# MMCHS1 register map
Vendor: Texas Instruments
Registers are 32-bit, access per field, reset 0x0 unless marked. A register's access mark holds for its fields unless they carry their own. Offsets are as the file gives them; [hi:lo] are bit positions; {n}, {i} and the like mark numbered series.

## MMCHS1 (part 2 of 2)
0x00 MMCHS_HL_REV ro reset not defined — IP Revision Identifier (X.Y.R) Used by software to track features, bugs, and compatibility
  [31:0] REVISION — IP Revision.
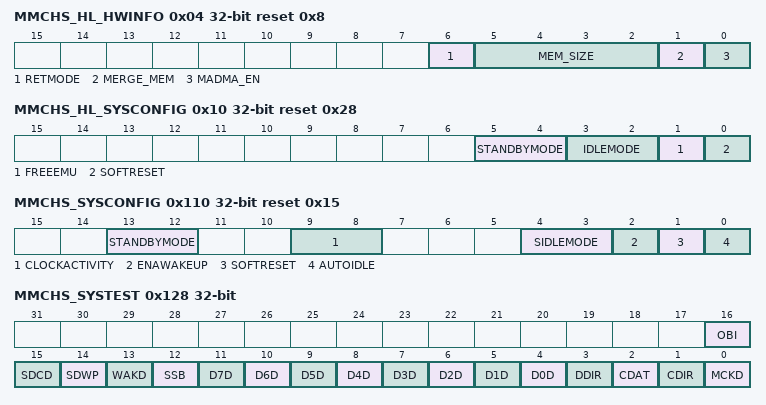
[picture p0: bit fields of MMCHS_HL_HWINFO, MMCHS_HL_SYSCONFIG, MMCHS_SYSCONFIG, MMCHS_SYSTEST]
0x04 MMCHS_HL_HWINFO ro reset 0x8 (reset mask 0xFFFFFFBE) — Information about the IP module's hardware configuration, that is, typically the module's HDL generics (if any). Actual field format and encoding is up to the module's designer to decide.
  [6] RETMODE — Retention mode generic parameter This bit field indicates whether the retention mode is supported using the pin PIRFFRET.
    0=Retention mode disabled; 1=Retention mode enabled
  [5:2] MEM_SIZE — Memory size for FIFO buffer:
    1=MEM_SIZE_1_r (Memory of 512 bytes, max block length is 512 bytes); 2=MEM_SIZE_2_r (Memory of 1024 bytes, max block length is 1024 bytes); 4=MEM_SIZE_4_r (Memory of 2048 bytes, max block length is 2048 bytes); 8=MEM_SIZE_8_r (Memory of 4096 bytes, max block length is 2048 bytes)
  [1] MERGE_MEM — Memory merged for FIFO buffer: This register defines the configuration of FIFO buffer architecture. If the bit is set STA and DFT shall support clock multiplexing and balancing.
    0=MERGE_MEM_0_r (2 memories instantiated, one per data transfer direction.); 1=MERGE_MEM_1_r (A single memory is used with multiplexed addresses, data and clocks.)
  [0] MADMA_EN — Master DMA enabled generic parameter: This register defines the configuration of the controller to know if it supports the master DMA management called ADMA.
    0=MADMA_EN_0_r (No Master DMA (ADMA) management supported); 1=MADMA_EN_1_r (Controller supports ADMA)
0x10 MMCHS_HL_SYSCONFIG reset 0x28 — Clock management configuration
  [5:4] STANDBYMODE rw — Configuration of the local initiator state management mode. By definition, initiator may generate read/write transaction as long as it is out of STANDBY state.
    0=Force-standby mode: local initiator is unconditionally placed in standby state.Backup mode, for debug only; 1=No-standby mode: local initiator is unconditionally placed out of standby state.Backup mode, for debug only; 2=Smart-standby mode: local initiator standby status depends on local conditions, that is, the module's functional requirement from the initiator.IP module shall not generate (initiator-related) wakeup events; 3=Smart-Standby wakeup-capable mode: local initiator standby status depends on local conditions, that is, the module's functional requirement from the initiator. IP module may generate (master-related) wakeup events when in standby state.Mode is only relevant if the appropriate IP module 'mwakeup' output is implemented.
  [3:2] IDLEMODE rw — Configuration of the local target state management mode. By definition, target can handle read/write transaction as long as it is out of IDLE state.
    0=Force-idle mode: local target's idle state follows (acknowledges) the system's idle requests unconditionally, that is, regardless of the IP module's internal requirements.Backup mode, for debug only; 1=No-idle mode: local target never enters idle state.Backup mode, for debug only; 2=Smart-idle mode: local target's idle state eventually follows (acknowledges) the system's idle requests, depending on the IP module's internal requirements.IP module shall not generate (IRQ- or DMA-request-related) wakeup events; 3=Smart-idle wakeup-capable mode: local target's idle state eventually follows (acknowledges) the system's idle requests, depending on the IP module's internal requirements.IP module may generate (IRQ- or DMA-request-related) wakeup events when in idle state.Mode is only relevant if the appropriate IP module 'swakeup' output(s) is (are) implemented
  [1] FREEEMU rw — Sensitivity to emulation (debug) suspend input signal. Functionality NOT implemented in MMCHS.
    0=IP module is sensitive to emulation suspend; 1=IP module is not sensitive to emulation suspend
  [0] SOFTRESET rw — Software reset. (Optional)
    0=SOFTRESET_0_w (No action); 0=SOFTRESET_0_r (Reset done, no pending action); 1=SOFTRESET_1_r (Reset (software or other) ongoing); 1=SOFTRESET_1_w (Initiate software reset)
0x110 MMCHS_SYSCONFIG reset 0x15 — System Configuration Register This register allows controlling various parameters of the Interconnect interface.
  [13:12] STANDBYMODE rw — Master interface power Management, standby/wait control. The bit field is only useful when generic parameter MMCHS_HL_HWINFO[0] MADMA_EN (Master ADMA enable) is set as active, otherwise it is a read only register read a 0.
    0=Force-standby. Mstandby is forced unconditionnaly.; 1=No-standby. Mstandby is never asserted.; 2=Smart-standby mode: local initiator standby status depends on local conditions, that is, the module's functional requirement from the initiator.IP module shall not generate (initiator-related) wakeup events; 3=Smart-Standby wakeup-capable mode: local initiator standby status depends on local conditions, that is, the module's functional requirement from the initiator. IP module may generate (master-related) wakeup events when in standby state.Mode is only relevant if the appropriate IP module 'mwakeup' output is implemented.
  [9:8] CLOCKACTIVITY rw — Clocks activity during wake up mode period. Bit8: Interface clock Bit9: Functional clock
    0=Interface and Functional clock may be switched off; 1=Interface clock is maintained. Functional clock may be switched-off.; 2=Functional clock is maintained. Interface clock may be switched-off.; 3=Interface and Functional clocks are maintained
  [4:3] SIDLEMODE rw — Power management
    0=If an idle request is detected, the MMCHS acknowledges it unconditionally and goes in Inactive mode. Interrupt and DMA requests are unconditionally de-asserted.; 1=If an idle request is detected, the request is ignored and the module keeps on behaving normally; 2=Smart-idle mode: local target's idle state eventually follows (acknowledges) the system's idle requests, depending on the IP module's internal requirements.IP module shall not generate (IRQ- or DMA-request-related) wakeup events; 3=Smart-idle wakeup-capable mode: local target's idle state eventually follows (acknowledges) the system's idle requests, depending on the IP module's internal requirements.IP module may generate (IRQ- or DMA-request-related) wakeup events when in idle state.Mode is only relevant if the appropriate IP module 'swakeup' output(s) is (are) implemented
  [2] ENAWAKEUP rw — Wakeup feature control
    0=Wakeup capability is disabled; 1=Wakeup capability is enabled
  [1] SOFTRESET rw — Software reset. The bit is automatically reset by the hardware. During reset, it always returns 0.
    0=SOFTRESET_0_r (Normal mode); 0=SOFTRESET_0_w (No effect.); 1=SOFTRESET_1_w (Trigger a module reset.); 1=SOFTRESET_1_r (The module is reset.)
  [0] AUTOIDLE rw — Internal Clock gating strategy
    0=Clocks are free-running; 1=Automatic clock gating strategy is applied, based on the Interconnect and MMC interface activity
0x114 MMCHS_SYSSTATUS ro — System Status Register This register provides status information about the module excluding the interrupt status information
  [0] RESETDONE — Internal Reset Monitoring Note: the debounce clock , the system clock (Interface) and the functional clock shall be provided to the MMC/SD/SDIO host controller to allow the internal reset monitoring.
    0=RESETDONE_0_r (Internal module reset is on-going); 1=RESETDONE_1_r (Reset completed.)
0x124 MMCHS_CSRE rw — Card status response error This register enables the host controller to detect card status errors of response type R1, R1b for all cards and of R5, R5b and R6 response for cards types SD or SDIO. When a bit [i] is set to 1, if the corresponding bit at the same position in the response [i] is set to 1, the host controller indicates a card error ([CERR]) interrupt status to avoid the host driver reading the response register (). Note: No automatic card error detection for autoCMD12 is implemented; the host system has to check autoCMD12 response register () for possible card errors.
  [31:0] CSRE — Card status response error
0x128 MMCHS_SYSTEST — System Test register This register is used to control the signals that connect to I/O pins when the module is configured in system test (SYSTEST) mode for boundary connectivity verification. Note: In SYSTEST mode, a write into register will not start a transfer. The buffer behaves as a stack accessible only by the local host (push and pop operations). In this mode, the Transfer Block Size ([11:0] BLEN) and the Blocks count for current transfer ([31:16] NBLK) are needed to generate a Buffer write ready interrupt ([4] BWR) or a Buffer read ready interrupt ([5] BRR) and DMA requests if enabled.
  [16] OBI rw — Out-Of-Band Interrupt (OBI) data value
    0=OBI_0_r (The Out-of-Band Interrupt pin is driven low.); 1=OBI_1_r (The Out-of-Band Interrupt pin is driven high.)
  [15] SDCD ro — Card detect input signal (SDCD) data value
    0=SDCD_0_r (The card detect pin is driven low.); 1=SDCD_1_r (The card detect pin is driven high.)
  [14] SDWP ro — Write protect input signal (SDWP) data value
    0=SDWP_0_r (The write protect pin SDWP is driven low.); 1=SDWP_1_r (The write protect pin SDWP is driven high.)
  [13] WAKD rw — Wake request output signal data value
    0=WAKD_0_w (The pin SWAKEUP is driven low.); 0=WAKD_0_r (No action. Returns 0.); 1=WAKD_1_w (The pin SWAKEUP is driven high.); 1=WAKD_1_r (No action. Returns 1.)
  [12] SSB rw — Set status bit This bit must be cleared prior attempting to clear a status bit of the interrupt status register (MMCHS_STAT).
    0=SSB_0_w (Clear this SSB bit field. Writing 0 does not clear already set status bits;); 0=SSB_0_r (No action. Returns 0.); 1=SSB_1_r (No action. Returns 1.); 1=SSB_1_w (Force to 1 all status bits of the interrupt status register () only if the corresponding bit field in the Interrupt signal enable register () is set.)
  [11] D7D rw — DAT7 input/output signal data value
    0=D7D_0_r (If[3] DDIR = 1 (input mode direction), returns the value on the DAT7 line (low). If [3] DDIR = 0 (output mode direction), returns 0); 0=D7D_0_w (If[3] DDIR = 0 (output mode direction), the DAT7 line is driven low. If [3] DDIR = 1 (input mode direction), no effect.); 1=D7D_1_r (If[3] DDIR = 1 (input mode direction), returns the value on the DAT7 line (high) If [3] DDIR = 0 (output mode direction), returns 1); 1=D7D_1_w (If[3] DDIR = 0 (output mode direction), the DAT7 line is driven high. If [3] DDIR = 1 (input mode direction), no effect.)
  [10] D6D rw — DAT6 input/output signal data value
    0=D6D_0_r (If SYSTEST[DDIR] = 1 (input mode direction), returns the value on the DAT6 line (low). If [3] DDIR = 0 (output mode direction), returns 0); 0=D6D_0_w (If[3] DDIR = 0 (output mode direction), the DAT6 line is driven low. If [3] DDIR = 1 (input mode direction), no effect.); 1=D6D_1_r (If[3] DDIR = 1 (input mode direction), returns the value on the DAT6 line (high) If [3] DDIR = 0 (output mode direction), returns 1); 1=D6D_1_w (If[3] DDIR = 0 (output mode direction), the DAT6 line is driven high. If [3] DDIR = 1 (input mode direction), no effect.)
  [9] D5D rw — DAT5 input/output signal data value
    0=D5D_0_r (If[3] DDIR = 1 (input mode direction), returns the value on the DAT5 line (low). If [3] DDIR = 0 (output mode direction), returns 0); 0=D5D_0_w (If[3] DDIR = 0 (output mode direction), the DAT5 line is driven low. If [3] DDIR = 1 (input mode direction), no effect.); 1=D5D_1_r (If[3] DDIR = 1 (input mode direction), returns the value on the DAT5 line (high) If [3] DDIR = 0 (output mode direction), returns 1); 1=D5D_1_w (If[3] DDIR = 0 (output mode direction), the DAT5 line is driven high. If [3] DDIR = 1 (input mode direction), no effect.)
  [8] D4D rw — DAT4 input/output signal data value
    0=D4D_0_w (If[3] DDIR = 0 (output mode direction), the DAT4 line is driven low. If [3] DDIR = 1 (input mode direction), no effect.); 0=D4D_0_r (If[3] DDIR = 1 (input mode direction), returns the value on the DAT4 line (low). If [3] DDIR = 0 (output mode direction), returns 0); 1=D4D_1_w (If[3] DDIR = 0 (output mode direction), the DAT4 line is driven high. If [3] DDIR = 1 (input mode direction), no effect.); 1=D4D_1_r (If[3] DDIR = 1 (input mode direction), returns the value on the DAT4 line (high) If [3] DDIR = 0 (output mode direction), returns 1)
  [7] D3D rw — DAT3 input/output signal data value
    0=D3D_0_w (If[3] DDIR = 0 (output mode direction), the DAT3 line is driven low. If [3] DDIR = 1 (input mode direction), no effect.); 0=D3D_0_r (If[3] DDIR = 1 (input mode direction), returns the value on the DAT3 line (low). If [3] DDIR = 0 (output mode direction), returns 0); 1=D3D_1_r (If[3] DDIR = 1 (input mode direction), returns the value on the DAT3 line (high) If [3] DDIR = 0 (output mode direction), returns 1); 1=D3D_1_w (If[3] DDIR = 0 (output mode direction), the DAT3 line is driven high. If [3] DDIR = 1 (input mode direction), no effect.)
  [6] D2D rw — DAT2 input/output signal data value
    0=D2D_0_w (If[3] DDIR = 0 (output mode direction), the DAT2 line is driven low. If [3] DDIR = 1 (input mode direction), no effect.); 0=D2D_0_r (If[3] DDIR = 1 (input mode direction), returns the value on the DAT2 line (low). If [3] DDIR = 0 (output mode direction), returns 0); 1=D2D_1_w (If[3] DDIR = 0 (output mode direction), the DAT2 line is driven high. If [3] DDIR = 1 (input mode direction), no effect.); 1=D2D_1_r (If[3] DDIR = 1 (input mode direction), returns the value on the DAT2 line (high) If [3] DDIR = 0 (output mode direction), returns 1)
  [5] D1D rw — DAT1 input/output signal data value
    0=D1D_0_r (If[3] DDIR = 1 (input mode direction), returns the value on the DAT1 line (low). If [3] DDIR = 0 (output mode direction), returns 0); 0=D1D_0_w (If[3] DDIR = 0 (output mode direction), the DAT1 line is driven low. If [3] DDIR = 1 (input mode direction), no effect.); 1=D1D_1_r (If[3] DDIR = 1 (input mode direction), returns the value on the DAT1 line (high) If [3] DDIR = 0 (output mode direction), returns 1); 1=D1D_1_w (If[3] DDIR = 0 (output mode direction), the DAT1 line is driven high. If [3] DDIR = 1 (input mode direction), no effect.)
  [4] D0D rw — DAT0 input/output signal data value
    0=D0D_0_w (If[3] DDIR = 0 (output mode direction), the DAT0 line is driven low. If [3] DDIR = 1 (input mode direction), no effect.); 0=D0D_0_r (If[3] DDIR = 1 (input mode direction), returns the value on the DAT0 line (low). If [3] DDIR = 0 (output mode direction), returns 0); 1=D0D_1_w (If[3] DDIR = 0 (output mode direction), the DAT0 line is driven high. If [3] DDIR = 1 (input mode direction), no effect.); 1=D0D_1_r (If[3] DDIR = 1 (input mode direction), returns the value on the DAT0 line (high) If [3] DDIR = 0 (output mode direction), returns 1)
  [3] DDIR rw — Control of the DAT[7:0] pins direction.
    0=DDIR_0_w (The DAT lines are outputs (host to card)); 0=DDIR_0_r (No action. Returns 0.); 1=DDIR_1_r (No action. Returns 1.); 1=DDIR_1_w (The DAT lines are inputs (card to host))
  [2] CDAT rw — CMD input/output signal data value
    0=CDAT_0_w (If[1] CDIR = 0 (output mode direction), the CMD line is driven low. If [1] CDIR = 1 (input mode direction), no effect.); 0=CDAT_0_r (If[1] CDIR = 1 (input mode direction), returns the value on the CMD line (low). If [1] CDIR = 0 (output mode direction), returns 0); 1=CDAT_1_w (If[1] CDIR = 0 (output mode direction), the CMD line is driven high. If [1] CDIR = 1 (input mode direction), no effect.); 1=CDAT_1_r (If[1] CDIR = 1 (input mode direction), returns the value on the CMD line (high) If [1] CDIR = 0 (output mode direction), returns 1)
  [1] CDIR rw — Control of the CMD pin direction.
    0=CDIR_0_r (No action. Returns 0.); 0=CDIR_0_w (The CMD line is an output (host to card)); 1=CDIR_1_r (No action. Returns 1.); 1=CDIR_1_w (The CMD line is an input (card to host))
  [0] MCKD rw — MMC clock output signal data value
    0=MCKD_0_r (No action. Returns 0.); 0=MCKD_0_w (The output clock is driven low.); 1=MCKD_1_w (The output clock is driven high.); 1=MCKD_1_r (No action. Returns 1.)
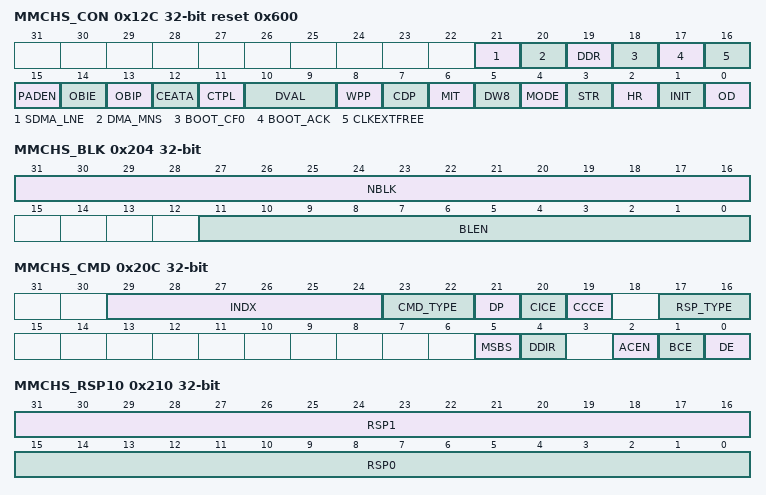
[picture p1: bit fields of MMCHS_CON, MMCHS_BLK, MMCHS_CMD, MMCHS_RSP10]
0x12C MMCHS_CON reset 0x600 — Configuration register This register is used: - to select the functional mode or the SYSTEST mode for any card. - to send an initialization sequence to any card. - to enable the detection on DAT[1] of a card interrupt for SDIO cards only. and also to configure : - specific data and command transfers for MMC cards only. - the parameters related to the card detect and write protect input signals.
  [21] SDMA_LNE rw — Slave DMA Level/Edge Request: The waveform of the DMA request can be configured either edge sensitive with early de-assertion on first access to MMCHS_DATA register or late de-assertion, request remains active until last allowed data written into MMCHS_DATA.
    0=Slave DMA edge sensitive, Early DMA de-assertion; 1=Slave DMA level sensitive, Late DMA de-assertion
  [20] DMA_MNS rw — DMA Master or Slave selection: When this bit is set and the controller is configured to use the DMA, Interconnect master interface is used to get datas from system using ADMA2 procedure (direct access to the memory).This option is only available if generic parameter MMCHS_HL_HWINFO[0] MADMA_EN is asserted to 1.
    0=The controller is slave on data transfers with system; 1=The controller is master on data exchange with system, controller must be configured as using DMA
  [19] DDR rw — Dual Data Rate mode: When this register is set, the controller uses both clock edge to emit or receive data. Odd bytes are transmitted on falling edges and even bytes are transmitted on rise edges. It only applies on Data bytes and CRC, Start, end bits and CRC status are kept full cycle. This bit field is only meaningful and active for even clock divider ratio of MMCHS_SYSCTL[15:6] CLKD, it is insensitive to MMCHS_HCTL[2] HSPE setting.
    0=Standard mode : data are transmitted on a single edge depending on[2] HSPE; 1=Data Bytes and CRC are transmitted on both edge
  [18] BOOT_CF0 rw — Boot status supported: This register is set when the CMD line need to be forced to 0 for a boot sequence. CMD line is driven to 0 after writing in MMCHS_CMD. The line is released when this bit field is de-asserted and abort data transfer in case of a pending transaction.
    0=BOOT_CF0_0_w (CMD line is released when it was previously forced to 0 by a boot sequence.); 0=BOOT_CF0_0_r (CMD line not forced); 1=BOOT_CF0_1_r (CMD line forced to 0 is enabled); 1=BOOT_CF0_1_w (CMD line forced to 0 is enabled and will be active after writing into)
  [17] BOOT_ACK rw — Book acknowledge received: When this bit is set the controller should receive a boot status on DAT0 line after next command issued. If no status is received a data timeout will be generated.
    0=No acknowledge to be received; 1=A boot status will be received on DAT0 line after issuing a command
  [16] CLKEXTFREE rw — External clock free running: This register is used to maintain card clock out of transfer transaction to enable slave module for example to generate a synchronous interrupt on DAT[1]. The Clock will be maintain only if MMCHS_SYSCTL[2] CEN is set.
    0=External card clock is cut off outside active transaction period; 1=External card clock is maintain even out of active transaction period only if[2] CEN is set
  [15] PADEN rw — Control Power for MMC Lines: This register is only useful when MMC PADs contain power saving mechanism to minimize its leakage power. It works as a GPIO that directly control the ACTIVE pin of PADs. Excepted for DAT[1], the signal is also combine outside the module with the dedicated power control MMCHS_CON[11] CTPL bit.
    0=ADPIDLE module pin is not forced, it is automatically generated by the MMC fsms; 1=ADPIDLE module pin is forced to active state
  [14] OBIE rw — Out-of-Band Interrupt Enable MMC cards only: This bit enables the detection of Out-of-Band Interrupt on MMCOBI input pin. The usage of the Out-of-Band signal (OBI) is optional and depends on the system integration.
    0=Out-of-Band interrupt detection disabled; 1=Out-of-Band interrupt detection enabled
  [13] OBIP rw — Out-of-Band Interrupt Polarity MMC cards only: This bit selects the active level of the out-of-band interrupt coming from MMC cards. The usage of the Out-of-Band signal (OBI) is optional and depends on the system integration.
    0=active high level; 1=active low level
  [12] CEATA rw — CE-ATA control mode MMC cards compliant with CE-ATA:By default, this bit is set to 0. It is use to indicate that next commands are considered as specific CE-ATA commands that potentially use 'command completion' features.
    0=Standard MMC/SD/SDIO mode; 1=CE-ATA mode next commands are considered as CE-ATA commands
  [11] CTPL rw — Control Power for DAT[1] line MMC and SD cards: By default, this bit is set to 0 and the host controller automatically disables all the input buffers outside of a transaction to minimize the leakage current. SDIO cards: When this bit is set to 1, the host controller automatically disables all the input buffers except the buffer of DAT[1] outside of a transaction in order to detect asynchronous card interrupt on DAT[1] line and minimize the leakage current of the buffers.
    0=Disable all the input buffers outside of a transaction; 1=Disable all the input buffers except the buffer of DAT[1] outside of a transaction
  [10:9] DVAL rw — Debounce filter value All cards This register is used to define a debounce period to filter the card detect input signal (SDCD). The usage of the card detect input signal (SDCD) is optional and depends on the system integration and the type of the connector housing that accommodates the card.
    0=33 us debounce period; 1=231 us debounce period; 2=1 ms debounce period; 3=8,4 ms debounce period
  [8] WPP rw — Write protect polarity For SD and SDIO cards only This bit selects the active level of the write protect input signal (SDWP). The usage of the write protect input signal (SDWP) is optional and depends on the system integration and the type of the connector housing that accommodates the card.
    0=active high level; 1=active low level
  [7] CDP rw — Card detect polarity All cards This bit selects the active level of the card detect input signal (SDCD). The usage of the card detect input signal (SDCD) is optional and depends on the system integration and the type of the connector housing that accommodates the card.
    0=active high level; 1=active low level
  [6] MIT rw — MMC interrupt command Only for MMC cards. This bit must be set to 1, when the next write access to the command register (MMCHS_CMD) is for writing a MMC interrupt command (CMD40) requiring the command timeout detection to be disabled for the command response.
    0=Command timeout enabled; 1=Command timeout disabled
  [5] DW8 rw — 8-bit mode MMC select For SD/SDIO cards, this bit must be set to 0. For MMC card, this bit must be set following a valid SWITCH command (CMD6) with the correct value and extend CSD index written in the argument. Prior to this command, the MMC card configuration register (CSD and EXT_CSD) must be verified for compliancy with MMC standard specification 4.x (see section 3.6).
    0=1-bit or 4-bit Data width (DAT[0] used, MMC, SD cards); 1=8-bit Data width (DAT[7:0] used, MMC cards)
  [4] MODE rw — Mode select All cards These bits select between Functional mode and SYSTEST mode.
    0=Functional mode. Transfers to the MMC/SD/SDIO cards follow the card protocol. MMC clock is enabled. MMC/SD transfers are operated under the control of the CMD register.; 1=SYSTEST mode The signal pins are configured as general-purpose input/output and the 1024-byte buffer is configured as a stack memory accessible only by the local host or system DMA. The pins retain their default type (input, output or in-out). SYSTEST mode is operated under the control of the SYSTEST register.
  [3] STR rw — Stream command Only for MMC cards. This bit must be set to 1 only for the stream data transfers (read or write) of the adtc commands. Stream read is a class 1 command (CMD11: READ_DAT_UNTIL_STOP). Stream write is a class 3 command (CMD20: WRITE_DAT_UNTIL_STOP).
    0=Block oriented data transfer; 1=Stream oriented data transfer
  [2] HR rw — Broadcast host response Only for MMC cards. This register is used to force the host to generate a 48-bit response for bc command type. It can be used to terminate the interrupt mode by generating a CMD40 response by the core (see section 4.3, 'Interrupt Mode', in the MMC [1] specification). In order to have the host response to be generated in open drain mode, the register MMCHS_CON[0] OD must be set to 1. When MMCHS_CON[12] CEATA is set to 1 and MMCHS_ARG set to 0x00000000 when writing 0x00000000 into MMCHS_CMD register, the host controller performs a 'command completion signal disable' token that is, CMD line held to 0 during 47 cycles followed by a 1.
    0=The host does not generate a 48-bit response instead of a command; 1=The host generates a 48-bit response instead of a command or a command completion signal disable token
  [1] INIT rw — Send initialization stream All cards. When this bit is set to 1, and the card is idle, an initialization sequence is sent to the card. An initialization sequence consists of setting the CMD line to 1 during 80 clock cycles. The initialisation sequence is mandatory - but it is not required to do it through this bit - this bit makes it easier. Clock divider (MMCHS_SYSCTL[15:6] CLKD) should be set to ensure that 80 clock periods are greater than 1ms. (see section 9.3, 'Power-Up', in the MMC card specification [1], or section 6.4 in the SD card specification [2]). Note: in this mode, there is no command sent to the card and no response is expected
    0=The host does not send an initialization sequence; 1=The host sends an initialization sequence
  [0] OD rw — Card open drain mode. Only for MMC cards. This bit must be set to 1 for MMC card commands 1, 2, 3 and 40, and if the MMC card bus is operating in open-drain mode during the response phase to the command sent. Typically, during card identification mode when the card is either in idle, ready or ident state. It is also necessary to set this bit to 1, for a broadcast host response (see Broadcast host response register MMCHS_CON[2] HR)
    0=No Open Drain; 1=Open Drain or Broadcast host response
0x130 MMCHS_PWCNT — Power counter register This register is used to program a mmc counter to delay command transfers after activating the PAD power, this value depends on PAD characteristics and voltage.
  [15:0] PWRCNT rw — Power counter register. This register is used to introduce a delay between the PAD ACTIVE pin assertion and the command issued.
    0=No additional delay added; 1=TCF delay (card clock period); 2=TCF x 2 delay (card clock period); 0xFFFE=TCF x 65534 delay (card clock period); 0xFFFF=TCF x 65535 delay (card clock period)
0x204 MMCHS_BLK — Transfer Length Configuration register [11:0] BLEN is the block size register. [31:16] NBLK is the block count register. This register shall be used for any card.
  [31:16] NBLK rw — Blocks count for current transfer This register is enabled when Block count Enable (MMCHS_CMD[1] BCE) is set to 1 and is valid only for multiple block transfers. Setting the block count to 0 results no data blocks being transferred. Note: The host controller decrements the block count after each block transfer and stops when the count reaches zero. This register can be accessed only if no transaction is executing (i.e, after a transaction has stopped). Read operations during transfers may return an invalid value and write operation will be ignored. In suspend context, the number of blocks yet to be transferred can be determined by reading this register. When restoring transfer context prior to issuing a Resume command, The local host shall restore the previously saved block count.
    0=Stop count; 1=1 block; 2=2 blocks; 0xFFFF=65535 blocks
  [11:0] BLEN rw — Transfer Block Size. This register specifies the block size for block data transfers. Read operations during transfers may return an invalid value, and write operations are ignored. When a CMD12 command is issued to stop the transfer, a read of the BLEN field after transfer completion (MMCHS_STAT[1] TC set to 1) will not return the true byte number of data length while the stop occurs but the value written in this register before transfer is launched.
    0=No data transfer; 1=1 byte block length; 2=2 bytes block length; 3=3 bytes block length; 0x1FF=511 bytes block length; 0x200=512 bytes block length; 0x400=1024 bytes block length
0x208 MMCHS_ARG rw — Command argument Register This register contains command argument specified as bit 39-8 of Command-Format These registers must be initialized prior to sending the command itself to the card (write action into the register register). Only exception is for a command index specifying stuff bits in arguments, making a write unnecessary.
  [31:0] ARG — Command argument bits [31:0]
0x20C MMCHS_CMD — Command and transfer mode register [31:16] = the command register [15:0] = the transfer mode. This register configures the data and command transfers. A write into the most significant byte send the command. A write into [15:0] registers during data transfer has no effect. This register shall be used for any card. Note: In SYSTEST mode, a write into register will not start a transfer.
  [29:24] INDX rw — Command index Binary encoded value from 0 to 63 specifying the command number send to card
    {v}=CMD{v} or ACMD{v} (v=0..63)
  [23:22] CMD_TYPE rw — Command type This register specifies three types of special command: Suspend, Resume and Abort. These bits shall be set to 00b for all other commands.
    0=Others Commands; 1=CMD52 for writing 'Bus Suspend' in CCCR; 2=CMD52 for writing 'Function Select' in CCCR; 3=Abort command CMD12, CMD52 for writing ' I/O Abort' in CCCR
  [21] DP rw — Data present select This register indicates that data is present and DAT line shall be used. It must be set to 0 in the following conditions: - command using only CMD line - command with no data transfer but using busy signal on DAT[0] - Resume command
    0=Command with no data transfer; 1=Command with data transfer
  [20] CICE rw — Command Index check enable This bit must be set to 1 to enable index check on command response to compare the index field in the response against the index of the command. If the index is not the same in the response as in the command, it is reported as a command index error (MMCHS_STAT[19] CIE set to1) Note: The register CICE cannot be configured for an Auto CMD12, then index check is automatically checked when this command is issued.
    0=Index check disable; 1=Index check enable
  [19] CCCE rw — Command CRC check enable This bit must be set to 1 to enable CRC7 check on command response to protect the response against transmission errors on the bus. If an error is detected, it is reported as a command CRC error (MMCHS_STAT[17] CCRC set to 1). Note: The register CCCE cannot be configured for an Auto CMD12, and then CRC check is automatically checked when this command is issued.
    0=CRC7 check disable; 1=CRC7 check enable
  [17:16] RSP_TYPE rw — Response type This bits defines the response type of the command
    0=No response; 1=Response Length 136 bits; 2=Response Length 48 bits; 3=Response Length 48 bits with busy after response
  [5] MSBS rw — Multi/Single block select This bit must be set to 1 for data transfer in case of multi block command. For any others command this bit shall be set to 0.
    0=Single block. If this bit is 0, it is not necessary to set the register [31:16] NBLK.; 1=Multi block. When Block Count is disabled ([1] BCE is set to 0) in Multiple block transfers ([5] MSBS is set to 1), the module can perform infinite transfer.
  [4] DDIR rw — Data transfer Direction Select This bit defines either data transfer will be a read or a write.
    0=Data Write (host to card); 1=Data Read (card to host)
  [2] ACEN rw — Auto CMD12 Enable SDIO does not support this feature. When this bit is set to 1, the host controller issues a CMD12 automatically after the transfer completion of the last block. The Host Driver shall not set this bit to issue commands that do not require CMD12 to stop data transfer. In particular, safe commands do not require CMD12.
    0=Auto CMD12 disable; 1=Auto CMD12 enable or CCS detection enabled
  [1] BCE rw — Block Count Enable Multiple block transfers only. This bit is used to enable the block count register (MMCHS_BLK[31:16] NBLK). When Block Count is disabled (MMCHS_CMD[1] BCE is set to 0) in Multiple block transfers (MMCHS_CMD[5] MSBS is set to 1), the module can perform infinite transfer.
    0=Block count disabled for infinite transfer; 1=Block count enabled for multiple block transfer with known number of blocks
  [0] DE rw — DMA Enable This bit is used to enable DMA mode for host data access.
    0=DMA mode disable; 1=DMA mode enable
0x210 MMCHS_RSP10 ro — Command response[31:0] Register This 32-bit register holds bits positions [31:0] of command response type R1/R1b/R2/R3/R4/R5/R5b/R6
  [31:16] RSP1 — Command Response [31:16]
  [15:0] RSP0 — Command Response [15:0]
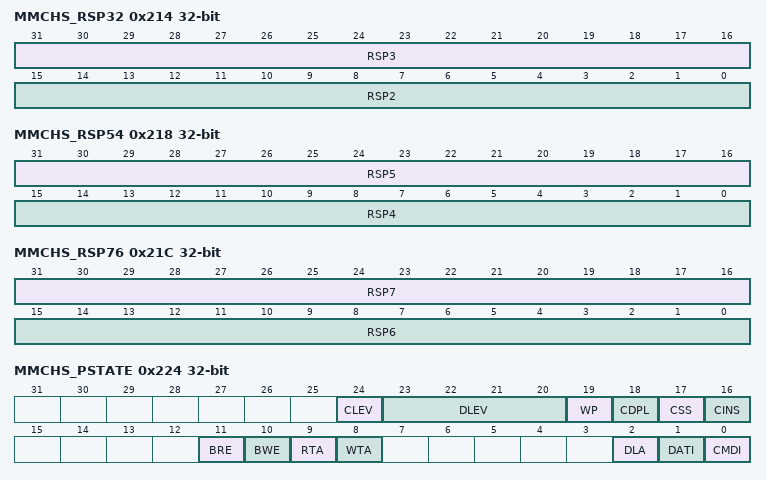
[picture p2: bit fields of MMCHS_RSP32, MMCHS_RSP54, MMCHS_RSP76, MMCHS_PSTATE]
0x214 MMCHS_RSP32 ro — Command response[63:32] Register This 32-bit register holds bits positions [63:32] of command response type R2
  [31:16] RSP3 — Command Response [63:48]
  [15:0] RSP2 — Command Response [47:32]
0x218 MMCHS_RSP54 ro — Command response[95:64] Register This 32-bit register holds bits positions [95:64] of command response type R2
  [31:16] RSP5 — Command Response [95:80]
  [15:0] RSP4 — Command Response [79:64]
0x21C MMCHS_RSP76 ro — Command response[127:96] Register This 32-bit register holds bits positions [127:96] of command response type R2
  [31:16] RSP7 — Command Response [127:112]
  [15:0] RSP6 — Command Response [111:96]
0x220 MMCHS_DATA rw — Data Register This register is the 32-bit entry point of the buffer for read or write data transfers. The buffer size is 32bits x256(1024 bytes). Bytes within a word are stored and read in little endian format. This buffer can be used as two 512 byte buffers to transfer data efficiently without reducing the throughput. Sequential and contiguous access is necessary to increment the pointer correctly. Random or skipped access is not allowed. In little endian, if the local host accesses this register byte-wise or 16bit-wise, the least significant byte (bits [7:0]) must always be written/read first. The update of the buffer address is done on the most significant byte write for full 32-bit DATA register or on the most significant byte of the last word of block transfer. Example 1: Byte or 16-bit access Mbyteen[3:0]=>0001 (1-byte) = Mbyteen[3:0]=0010 (1-byte) => Mbyteen[3:0]=1100 (2-bytes) OK Mbyteen[3:0]=>0001 (1-byte) = Mbyteen[3:0]=0010 (1-byte) => Mbyteen[3:0]=0100 (1-byte) OK Mbyteen[3:0]=>0001 (1-byte) = Mbyteen[3:0]=0010 (1-byte) => Mbyteen[3:0]=1000 (1-byte) Bad
  [31:0] DATA — Data Register [31:0] In functional mode (MMCHS_CON[4] MODE set to the default value 0) , A read access to this register is allowed only when the buffer read enable status is set to 1 (MMCHS_PSTATE[11] BRE), otherwise a bad access (MMCHS_STAT[29] BADA) is signaled. A write access to this register is allowed only when the buffer write enable status is set to 1(MMCHS_PSTATE[10] BWE), otherwise a bad access (MMCHS_STAT[29] BADA) is signaled and the data is not written.
0x224 MMCHS_PSTATE ro (reset mask 0xFE03FFFF) — Present state register The Host can get status of the Host Controller from this 32-bit read only register.
  [24] CLEV — CMD line signal level This status is used to check the CMD line level to recover from errors, and for debugging. The value of this register after reset depends on the CMD line level at that time.
    0=CLEV_0_r (The CMD line level is 0.); 1=CLEV_1_r (The CMD line level is 1.)
  [23:20] DLEV — DAT[3:0] line signal level DAT[3] =&gt; bit 23 DAT[2] =&gt; bit 22 DAT[1] =&gt; bit 21 DAT[0] =&gt; bit 20 This status is used to check DAT line level to recover from errors, and for debugging. This is especially useful in detecting the busy signal level from DAT[0]. The value of these registers after reset depends on the DAT lines level at that time.
  [19] WP — Write protect switch pin level For SDIO cards only. This bit reflects the write protect input pin (SDWP) level. The value of this register after reset depends on the protect input pin (SDWP) level at that time.
    0=WP_0_r (If[8] WPP is set to 0 (default), the card is write protected, otherwise the card is not protected.); 1=WP_1_r (If[8] WPP is set to 0 (default), the card is not write protected, otherwise the card is protected.)
  [18] CDPL — Card detect pin level This bit reflects the inverse value of the card detect input pin (SDCD), debouncing is not performed on this bit and bit is valid only when Card State Stable (MMCHS_PSTATE[17] CSS) is set to 1. Use of this bit is limited to testing since it must be debounced y software. The value of this register after reset depends on the card detect input pin (SDCD) level at that time.
    0=CDPL_0_r (The value of the card detect input pin (SDCD) is 1); 1=CDPL_1_r (The value of the card detect input pin (SDCD) is 0)
  [17] CSS — Card State Stable This bit is used for testing. It is set to 1 only when Card Detect Pin Level is stable (MMCHS_PSTATE[18] CDPL). Debouncing is performed on the card detect input pin (SDCD) to detect card stability. This bit is not affected by a software reset.
    0=CSS_0_r (Reset or Debouncing); 1=CSS_1_r (No card or card inserted)
  [16] CINS — Card inserted This bit is the debounced value of the card detect input pin (SDCD). An inactive to active transition of the card detect input pin (SDCD) will generate a card insertion interrupt (MMCHS_STAT[6] CINS). A active to inactive transition of the card detect input pin (SDCD) will generate a card removal interrupt (MMCHS_STAT[7] CREM). This bit is not affected by a software reset.
    0=CINS_0_r (If[7] CDP is set to 0 (default), no card is detected. The card may have been removed from the card slot. If [7] CDP is set to 1, the card has been inserted.); 1=CINS_1_r (If[7] CDP is set to 0 (default), the card has been inserted from the card slot. If [7] CDP is set to 1, no card is detected. The card may have been removed from the card slot.)
  [11] BRE — Buffer read enable This bit is used for non-DMA read transfers. It indicates that a complete block specified by MMCHS_BLK[11:0] BLEN has been written in the buffer and is ready to be read. It is set to 0 when the entire block is read from the buffer. It is set to 1 when a block data is ready in the buffer and generates the Buffer read ready status of interrupt (MMCHS_STAT[5] BRR).
    0=BRE_0_r (Read BLEN bytes disable); 1=BRE_1_r (Read BLEN bytes enable. Readable data exists in the buffer.)
  [10] BWE — Buffer Write enable This status is used for non-DMA write transfers. It indicates if space is available for write data.
    0=BWE_0_r (There is no room left in the buffer to write BLEN bytes of data.); 1=BWE_1_r (There is enough space in the buffer to write BLEN bytes of data.)
  [9] RTA — Read transfer active This status is used for detecting completion of a read transfer. It is set to 1 after the end bit of read command or by activating a continue request (MMCHS_HCTL[17] CR) following a stop at block gap request. This bit is set to 0 when all data have been read by the local host after last block or after a stop at block gap request.
    0=RTA_0_r (No valid data on the DAT lines.); 1=RTA_1_r (read data transfer on going.)
  [8] WTA — Write transfer active This status indicates a write transfer active. It is set to 1 after the end bit of write command or by activating a continue request (MMCHS_HCTL[17] CR) following a stop at block gap request. This bit is set to 0 when CRC status has been received after last block or after a stop at block gap request.
    0=WTA_0_r (No valid data on the DAT lines.); 1=WTA_1_r (Write data transfer on going.)
  [2] DLA — DAT line active This status bit indicates whether one of the DAT line is in use. In the case of read transactions (card to host): This bit is set to 1 after the end bit of read command or by activating continue request MMCHS_HCTL[17] CR. This bit is set to 0 when the host controller received the end bit of the last data block or at the beginning of the read wait mode. In the case of write transactions (host to card): This bit is set to 1 after the end bit of write command or by activating continue request MMCHS_HCTL[17] CR. This bit is set to 0 on the end of busy event for the last block; host controller must wait 8 clock cycles with line not busy to really consider not 'busy state' or after the busy block as a result of a stop at gap request.
    0=DLA_0_r (DAT Line inactive); 1=DLA_1_r (DAT Line active)
  [1] DATI — Command inhibit(DAT) This status bit is generated if either DAT line is active (MMCHS_PSTATE[2] DLA) or Read transfer is active (MMCHS_PSTATE[9] RTA) or when a command with busy is issued. This bit prevents the local host to issue a command. A change of this bit from 1 to 0 generates a transfer complete interrupt (MMCHS_STAT[1] TC).
    0=DATI_0_r (Issuing of command using the DAT lines is allowed); 1=DATI_1_r (Issuing of command using DAT lines is not allowed)
  [0] CMDI — Command inhibit(CMD) This status bit indicates that the CMD line is in use. This bit is set to 0 when the most significant byte is written into the command register. This bit is not set when Auto CMD12 is transmitted. This bit is set to 0 in either the following cases: - After the end bit of the command response, excepted if there is a command conflict error (MMCHS_STAT[17] CCRC or MMCHS_STAT[18] CEB set to 1) or a Auto CMD12 is not executed (MMCHS_AC12[0] ACNE). - After the end bit of the command without response (MMCHS_CMD[17:16] RSP_TYPE set to '00') In case of a command data error is detected (MMCHS_STAT[16] CTO set to 1), this register is not automatically cleared.
    0=CMDI_0_r (Issuing of command using CMD line is allowed); 1=CMDI_1_r (Issuing of command using CMD line is not allowed)
